# SAMA7G54D4GN8 register map
Vendor: Microchip Technology; Series: SAMA7G5; File version: 0
Registers are 32-bit, read-write, reset 0x0 unless marked. A register's access mark holds for its fields unless they carry their own. Offsets are from the block's base; [hi:lo] are bit positions; {n}, {i} and the like mark numbered series; 'fields as' and 'values as' point back to an identical list.

## TZC — TrustZone Address Space Controller
Base 0xE3000000
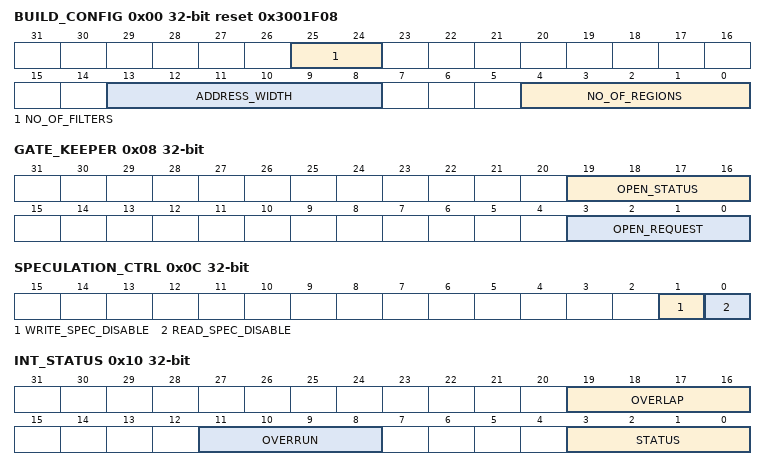
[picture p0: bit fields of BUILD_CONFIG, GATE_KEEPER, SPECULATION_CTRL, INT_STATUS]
0x00 BUILD_CONFIG ro reset 0x3001F08 — Build Configuration Register
  [25:24] NO_OF_FILTERS — Number of filters -minus one
  [13:8] ADDRESS_WIDTH — Address width minus one
  [4:0] NO_OF_REGIONS — Number of regions minus one
0x04 ACTION
  [1:0] REACTION_VALUE — Failure Reaction
0x08 GATE_KEEPER
  [19:16] OPEN_STATUS — Gate keeper open status
  [3:0] OPEN_REQUEST — Gate keeper open request
0x0C SPECULATION_CTRL — Speculation Control Register
  [1] WRITE_SPEC_DISABLE — Write speculation disable control
  [0] READ_SPEC_DISABLE — Read speculation disable control
0x10 INT_STATUS ro — Interrupt Status Register
  [19:16] OVERLAP — Interrupt status - overlap
  [11:8] OVERRUN — Interrupt status - overrun
  [3:0] STATUS — Interrupt status
0x14 INT_CLEAR wo — Interrupt Clear Register
  [3:0] CLEAR — Interrupt clear
{0x20+0x10*i} FAIL_ADDRESS_LOW_{i} ro (i=0..3) — Fail Address Low Register
  [31:0] ADDR_STATUS_LOW — Failure access's low address
{0x24+0x10*i} FAIL_ADDRESS_HIGH_{i} ro (i=0..3) — Fail Address High Register
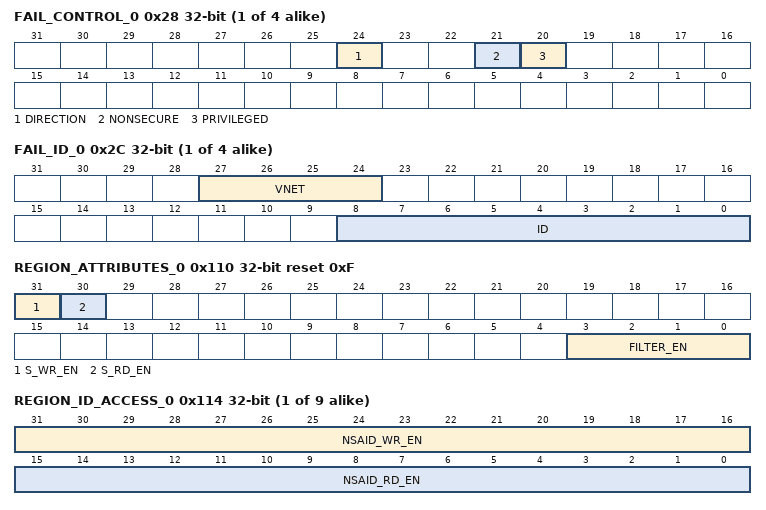
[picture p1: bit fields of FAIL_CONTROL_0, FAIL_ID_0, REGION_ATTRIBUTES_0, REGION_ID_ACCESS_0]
{0x28+0x10*i} FAIL_CONTROL_{i} ro (i=0..3) — Fail Control Register
  [24] DIRECTION — Failure access's direction
  [21] NONSECURE — Failure access's security value
  [20] PRIVILEGED — Failure access's privileged value
{0x2C+0x10*i} FAIL_ID_{i} ro (i=0..3) — Fail ID Register
  [27:24] VNET — Failure access's virtual network
  [8:0] ID — Failure access's ID
0x100 REGION_BASE_LOW_0 ro — Region 0 Base Address Low Register
  [31:12] BASE_ADDRESS_LOW_0 — Region base address lower 32bits.
0x104 REGION_BASE_HIGH_0 ro — Region 0 Base Address High Register
0x108 REGION_TOP_LOW_0 ro reset 0xFFFFFFFF — Region 0 Top Address Low Register
  [31:12] TOP_ADDRESS_LOW_0 — Region top address lower 32bits.
0x10C REGION_TOP_HIGH_0 ro — Region 0 Top Address High Register
0x110 REGION_ATTRIBUTES_0 reset 0xF — Region 0 Attribute Register
  [31] S_WR_EN — Region secure write enable
  [30] S_RD_EN — Region secure read enable
  [3:0] FILTER_EN — Region filter enables
{0x114+0x20*i} REGION_ID_ACCESS_{i} (i=0..8) — Region {i} ID Access Register
  [31:16] NSAID_WR_EN — Region non-secure access ID write enable
  [15:0] NSAID_RD_EN — Region non-secure access ID read enable
{0x100+0x20*i} REGION_BASE_LOW_{i} (i=1..8) — Region {i} Base Address Low Register
  [31:12] BASE_ADDRESS_LOW_{i} — Region base address lower 32bits.
{0x104+0x20*i} REGION_BASE_HIGH_{i} (i=1..8) — Region {i} Base Address High Register
{0x108+0x20*i} REGION_TOP_LOW_{i} reset 0xFFF (i=1..8) — Region {i} Top Address Low Register
  [31:12] TOP_ADDRESS_LOW_{i} — Region top address lower 32bits.
{0x10C+0x20*i} REGION_TOP_HIGH_{i} (i=1..8) — Region {i} Top Address High Register
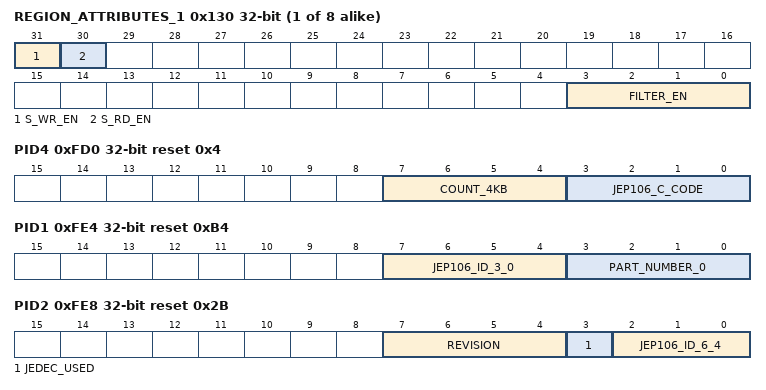
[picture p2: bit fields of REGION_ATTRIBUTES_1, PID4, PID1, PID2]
{0x110+0x20*i} REGION_ATTRIBUTES_{i} (i=1..8) — Region {i} Attribute Register
  fields as REGION_ATTRIBUTES_0
0xFD0 PID4 ro reset 0x4 — Peripheral Identification 4 Register
  [7:4] COUNT_4KB — Number of 4Kbyte address blocks
  [3:0] JEP106_C_CODE — JEP106 continuation code
{0xFC0+4i} PID{i} ro (i=5..7) — Peripheral Identification {i} Register
0xFE0 PID0 ro reset 0x60 — Peripheral Identification 0 Register
  [7:0] PART_NUMBER_0 — Part number lower 8 bits
0xFE4 PID1 ro reset 0xB4 — Peripheral Identification 1 Register
  [7:4] JEP106_ID_3_0 — JEP106 ARM's identification code bits 3 down to 0
  [3:0] PART_NUMBER_0 — Part number top 4 bits
0xFE8 PID2 ro reset 0x2B — Peripheral Identification 2 Register
  [7:4] REVISION
  [3] JEDEC_USED — Indicates the use of JEP106 manufacturer's identity code
  [2:0] JEP106_ID_6_4 — JEP106 ARM's identification code bits 6 down to 4
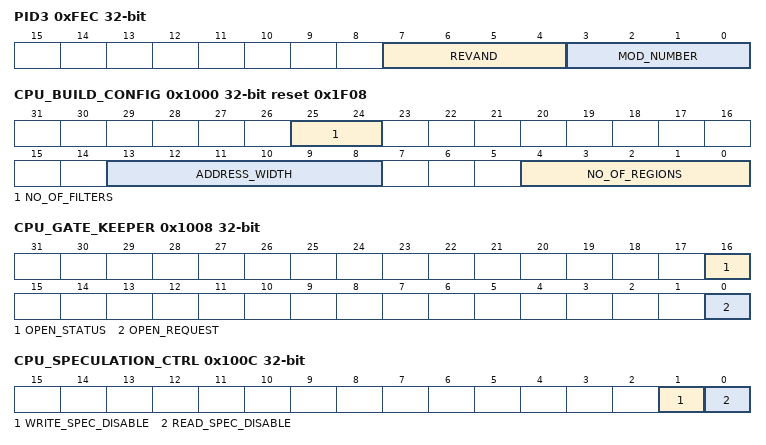
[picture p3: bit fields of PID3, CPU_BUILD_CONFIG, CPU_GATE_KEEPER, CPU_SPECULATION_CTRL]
0xFEC PID3 ro — Peripheral Identification 3 Register
  [7:4] REVAND — User Modifiable Revision Number
  [3:0] MOD_NUMBER — Modification Number
0xFF0 CID0 ro reset 0xD — Component Identification 0
  [7:0] COMP_ID_0 — Conponent identity 0
0xFF4 CID1 ro reset 0xF0 — Component Identification 1
  [7:0] COMP_ID_1 — Conponent identity 1
0xFF8 CID2 ro reset 0x5 — Component Identification 2
  [7:0] COMP_ID_2 — Conponent identity 2
0xFFC CID3 ro reset 0xB1 — Component Identification 3
  [7:0] COMP_ID_3 — Conponent identity 3
0x1000 CPU_BUILD_CONFIG ro reset 0x1F08 — Build Configuration Register [CPU]
  fields as BUILD_CONFIG
0x1004 CPU_ACTION — Action Register [CPU]
  [1:0] REACTION_VALUE — Failure Reaction
0x1008 CPU_GATE_KEEPER — Gate Keeper Register [CPU]
  [16] OPEN_STATUS — Gate keeper open status
  [0] OPEN_REQUEST — Gate keeper open request
0x100C CPU_SPECULATION_CTRL — Speculation Control Register [CPU]
  fields as SPECULATION_CTRL
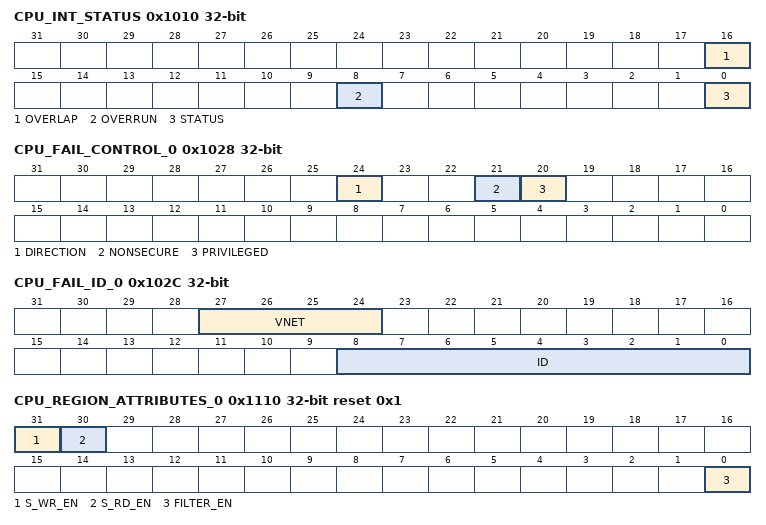
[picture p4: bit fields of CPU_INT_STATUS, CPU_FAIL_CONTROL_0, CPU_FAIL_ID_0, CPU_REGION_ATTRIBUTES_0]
0x1010 CPU_INT_STATUS ro — Interrupt Status Register [CPU]
  [16] OVERLAP — Interrupt status - overlap
  [8] OVERRUN — Interrupt status - overrun
  [0] STATUS — Interrupt status
0x1014 CPU_INT_CLEAR wo — Interrupt Clear Register [CPU]
  [0] CLEAR — Interrupt clear
0x1020 CPU_FAIL_ADDRESS_LOW_0 ro — Fail Address Low Register [CPU]
  [31:0] ADDR_STATUS_LOW — Failure access's low address
0x1024 CPU_FAIL_ADDRESS_HIGH_0 ro — Fail Address High Register [CPU]
0x1028 CPU_FAIL_CONTROL_0 ro — Fail Control Register [CPU]
  fields as FAIL_CONTROL_0
0x102C CPU_FAIL_ID_0 ro — Fail ID Register [CPU]
  fields as FAIL_ID_0
0x1100 CPU_REGION_BASE_LOW_0 ro — Region 0 Base Address Low Register [CPU]
  [31:12] BASE_ADDRESS_LOW_0 — Region base address lower 32bits.
0x1104 CPU_REGION_BASE_HIGH_0 ro — Region 0 Base Address High Register [CPU]
0x1108 CPU_REGION_TOP_LOW_0 ro reset 0xFFFFFFFF — Region 0 Top Address Low Register [CPU]
  [31:12] TOP_ADDRESS_LOW_0 — Region top address lower 32bits.
0x110C CPU_REGION_TOP_HIGH_0 ro — Region 0 Top Address High Register [CPU]
0x1110 CPU_REGION_ATTRIBUTES_0 reset 0x1 — Region 0 Attribute Register [CPU]
  [31] S_WR_EN — Region secure write enable
  [30] S_RD_EN — Region secure read enable
  [0] FILTER_EN — Region filter enables
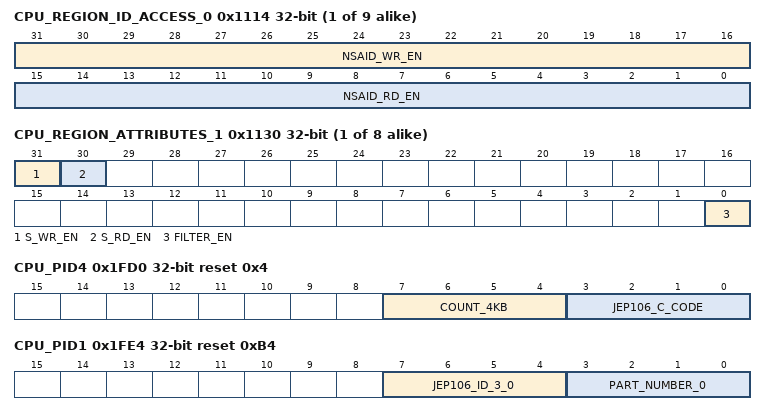
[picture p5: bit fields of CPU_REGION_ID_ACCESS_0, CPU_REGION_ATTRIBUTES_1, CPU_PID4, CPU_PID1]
{0x1114+0x20*i} CPU_REGION_ID_ACCESS_{i} (i=0..8) — Region {i} ID Access Register [CPU]
  fields as REGION_ID_ACCESS_0
{0x1100+0x20*i} CPU_REGION_BASE_LOW_{i} (i=1..8) — Region {i} Base Address Low Register [CPU]
  [31:12] BASE_ADDRESS_LOW_{i} — Region base address lower 32bits.
{0x1104+0x20*i} CPU_REGION_BASE_HIGH_{i} (i=1..8) — Region {i} Base Address High Register [CPU]
{0x1108+0x20*i} CPU_REGION_TOP_LOW_{i} reset 0xFFF (i=1..8) — Region {i} Top Address Low Register [CPU]
  [31:12] TOP_ADDRESS_LOW_{i} — Region top address lower 32bits.
{0x110C+0x20*i} CPU_REGION_TOP_HIGH_{i} (i=1..8) — Region {i} Top Address High Register [CPU]
{0x1110+0x20*i} CPU_REGION_ATTRIBUTES_{i} (i=1..8) — Region {i} Attribute Register [CPU]
  fields as CPU_REGION_ATTRIBUTES_0
0x1FD0 CPU_PID4 ro reset 0x4 — Peripheral Identification 4 Register [CPU]
  fields as PID4
{0x1FC0+4i} CPU_PID{i} ro (i=5..7) — Peripheral Identification {i} Register [CPU]
0x1FE0 CPU_PID0 ro reset 0x60 — Peripheral Identification 0 Register [CPU]
  [7:0] PART_NUMBER_0 — Part number lower 8 bits
0x1FE4 CPU_PID1 ro reset 0xB4 — Peripheral Identification 1 Register [CPU]
  fields as PID1
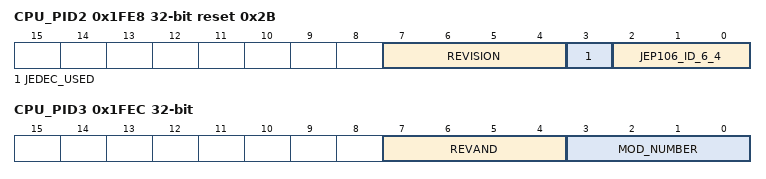
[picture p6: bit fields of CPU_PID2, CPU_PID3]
0x1FE8 CPU_PID2 ro reset 0x2B — Peripheral Identification 2 Register [CPU]
  fields as PID2
0x1FEC CPU_PID3 ro — Peripheral Identification 3 Register [CPU]
  fields as PID3
0x1FF0 CPU_CID0 ro reset 0xD — Component Identification 0 [CPU]
  [7:0] COMP_ID_0 — Conponent identity 0
0x1FF4 CPU_CID1 ro reset 0xF0 — Component Identification 1 [CPU]
  [7:0] COMP_ID_1 — Conponent identity 1
0x1FF8 CPU_CID2 ro reset 0x5 — Component Identification 2 [CPU]
  [7:0] COMP_ID_2 — Conponent identity 2
0x1FFC CPU_CID3 ro reset 0xB1 — Component Identification 3 [CPU]
  [7:0] COMP_ID_3 — Conponent identity 3
